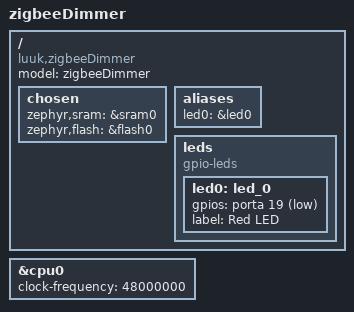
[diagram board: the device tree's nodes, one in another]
/*
 * Copyright (c) 2021 Argentum Systems Ltd.
 *
 * SPDX-License-Identifier: Apache-2.0
 */

/dts-v1/;
#include <atmel/samr30.dtsi>
#include "zigbeeDimmer-pinctrl.dtsi"
#include <zephyr/dt-bindings/input/input-event-codes.h>

/ {
	model = "zigbeeDimmer";
	compatible = "luuk,zigbeeDimmer", "atmel,samr30e18", "atmel,samr30";

	chosen {
		zephyr,sram = &sram0;
		zephyr,flash = &flash0;
	};

	/* These aliases are provided for compatibility with samples */
	aliases {
		led0 = &led0;
	};

	leds {
		compatible = "gpio-leds";
		led0: led_0 {
			gpios = <&porta 19 GPIO_ACTIVE_LOW>;
			label = "Red LED";
		};
	};
};

&cpu0 {
	clock-frequency = <48000000>;
};
